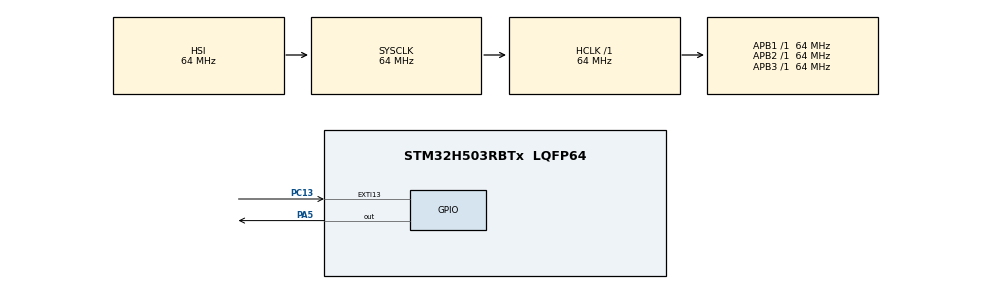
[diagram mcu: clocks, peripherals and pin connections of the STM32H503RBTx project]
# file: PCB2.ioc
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BOOTPATH.BootPathName=LEGACY
BOOTPATH.UserSelectedBootPath=LEGACY
Mcu.Family=STM32H5
Mcu.Name=STM32H503RBTx
Mcu.Package=LQFP64
NUCLEO-H503RB.BUTTON=1
NUCLEO-H503RB.LD2=true
NUCLEO-H503RB.VCP=true
NVIC.EXTI13_IRQn=true\:0\:0\:false\:false\:true\:false\:true\:true
NVIC.PriorityGroup=NVIC_PRIORITYGROUP_4
PA3.Signal=USART3_RX
PA4.Signal=USART3_TX
PA5.Signal=GPIO_Output
PC13.Signal=GPXTI13
ProjectManager.HeapSize=0x200
ProjectManager.StackSize=0x400
ProjectManager.TargetToolchain=STM32CubeIDE
RCC.ADCFreq_Value=64000000
RCC.AHBFreq_Value=64000000
RCC.APB1Freq_Value=64000000
RCC.APB1TimFreq_Value=64000000
RCC.APB2Freq_Value=64000000
RCC.APB2TimFreq_Value=64000000
RCC.APB3Freq_Value=64000000
RCC.CSI_VALUE=4000000
RCC.CortexFreq_Value=64000000
RCC.EPOD_VALUE=4000000
RCC.HCLKFreq_Value=64000000
RCC.HSE_VALUE=24000000
RCC.HSI48_VALUE=48000000
RCC.HSIDiv=RCC_HSI_DIV1
RCC.HSI_VALUE=64000000
RCC.LSE_VALUE=32768
RCC.LSIRC_VALUE=32000
RCC.PLLN=32
RCC.SYSCLKFreq_VALUE=64000000
RCC.USBFreq_Value=48000000
RCC.VCOOutputFreq_Value=128000000
VP_BOOTPATH_VS_BOOTPATH.Mode=BP_Activate
VP_CORTEX_M33_NS_VS_Hclk.Mode=Hclk_Mode
VP_MEMORYMAP_VS_MEMORYMAP.Mode=CurAppReg
VP_NUCLEO-H503RB_VS_BSP_COMMON.Mode=COMMON
VP_PWR_VS_DBSignals.Mode=DisableDeadBatterySignals
VP_PWR_VS_LPOM.Mode=PowerOptimisation
VP_PWR_VS_SECSignals.Mode=Security/Privilege
board=NUCLEO-H503RB

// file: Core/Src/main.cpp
/* USER CODE BEGIN Header */
/**
  ******************************************************************************
  * @file           : main.c
  * @brief          : Main program body
  ******************************************************************************
  * @attention
  *
  * Copyright (c) 2025 STMicroelectronics.
  * All rights reserved.
  *
  * This software is licensed under terms that can be found in the LICENSE file
  * in the root directory of this software component.
  * If no LICENSE file comes with this software, it is provided AS-IS.
  *
  ******************************************************************************
  */
/* USER CODE END Header */
#include "main.h"

/* USER CODE BEGIN Includes */
#include "Modules/LED.h"
/* USER CODE END Includes */

/* USER CODE BEGIN PD */
LED userLED;
/* USER CODE END PD */

COM_InitTypeDef BspCOMInit;

void SystemClock_Config(void);

int main(void)
{

  /* MCU Configuration--------------------------------------------------------*/

  /* Reset of all peripherals, Initializes the Flash interface and the Systick. */
  HAL_Init();

  /* Configure the system clock */
  SystemClock_Config();

  /* Initialize all configured peripherals */

  /* Initialize led */
  BSP_LED_Init(LED_GREEN);

  /* Initialize USER push-button, will be used to trigger an interrupt each time it's pressed.*/
  BSP_PB_Init(BUTTON_USER, BUTTON_MODE_EXTI);

  /* Initialize COM1 port (115200, 8 bits (7-bit data + 1 stop bit), no parity */
  BspCOMInit.BaudRate   = 115200;
  BspCOMInit.WordLength = COM_WORDLENGTH_8B;
  BspCOMInit.StopBits   = COM_STOPBITS_1;
  BspCOMInit.Parity     = COM_PARITY_NONE;
  BspCOMInit.HwFlowCtl  = COM_HWCONTROL_NONE;
  if (BSP_COM_Init(COM1, &BspCOMInit) != BSP_ERROR_NONE)
  {
    Error_Handler();
  }

  /* Infinite loop */
  /* USER CODE BEGIN WHILE */
  while (1)
  {
	  userLED.blink();

    /* USER CODE END WHILE */

  }
}

void SystemClock_Config(void)
{
  RCC_OscInitTypeDef RCC_OscInitStruct = {0};
  RCC_ClkInitTypeDef RCC_ClkInitStruct = {0};

  /** Configure the main internal regulator output voltage
  */
  __HAL_PWR_VOLTAGESCALING_CONFIG(PWR_REGULATOR_VOLTAGE_SCALE3);

  while(!__HAL_PWR_GET_FLAG(PWR_FLAG_VOSRDY)) {}

  /** Initializes the RCC Oscillators according to the specified parameters
  * in the RCC_OscInitTypeDef structure.
  */
  RCC_OscInitStruct.OscillatorType = RCC_OSCILLATORTYPE_HSI;
  RCC_OscInitStruct.HSIState = RCC_HSI_ON;
  RCC_OscInitStruct.HSIDiv = RCC_HSI_DIV1;
  RCC_OscInitStruct.HSICalibrationValue = RCC_HSICALIBRATION_DEFAULT;
  RCC_OscInitStruct.PLL.PLLState = RCC_PLL_NONE;
  if (HAL_RCC_OscConfig(&RCC_OscInitStruct) != HAL_OK)
  {
    Error_Handler();
  }

  /** Initializes the CPU, AHB and APB buses clocks
  */
  RCC_ClkInitStruct.ClockType = RCC_CLOCKTYPE_HCLK|RCC_CLOCKTYPE_SYSCLK
                              |RCC_CLOCKTYPE_PCLK1|RCC_CLOCKTYPE_PCLK2
                              |RCC_CLOCKTYPE_PCLK3;
  RCC_ClkInitStruct.SYSCLKSource = RCC_SYSCLKSOURCE_HSI;
  RCC_ClkInitStruct.AHBCLKDivider = RCC_SYSCLK_DIV1;
  RCC_ClkInitStruct.APB1CLKDivider = RCC_HCLK_DIV1;
  RCC_ClkInitStruct.APB2CLKDivider = RCC_HCLK_DIV1;
  RCC_ClkInitStruct.APB3CLKDivider = RCC_HCLK_DIV1;

  if (HAL_RCC_ClockConfig(&RCC_ClkInitStruct, FLASH_LATENCY_3) != HAL_OK)
  {
    Error_Handler();
  }

  /** Configure the programming delay
  */
  __HAL_FLASH_SET_PROGRAM_DELAY(FLASH_PROGRAMMING_DELAY_1);
}

void Error_Handler(void)
{
  __disable_irq();
  while (1)
  {
  }
}
